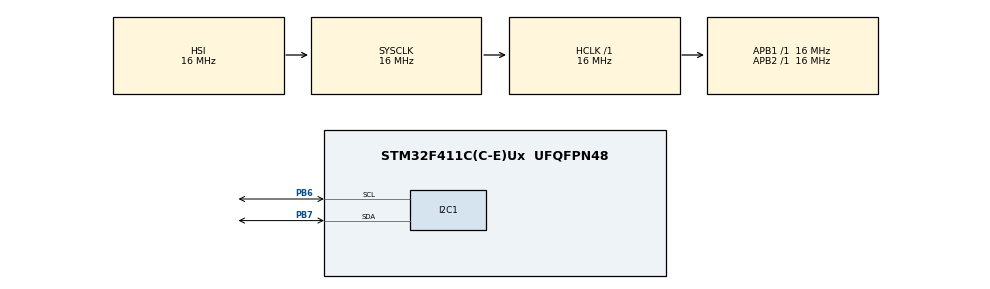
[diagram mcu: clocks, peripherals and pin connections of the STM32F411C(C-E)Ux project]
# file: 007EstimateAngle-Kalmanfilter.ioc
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Mcu.Family=STM32F4
Mcu.Name=STM32F411C(C-E)Ux
Mcu.Package=UFQFPN48
NVIC.PriorityGroup=NVIC_PRIORITYGROUP_4
PA13.Mode=Serial_Wire
PA13.Signal=SYS_JTMS-SWDIO
PA14.Mode=Serial_Wire
PA14.Signal=SYS_JTCK-SWCLK
PB6.Mode=I2C
PB6.Signal=I2C1_SCL
PB7.Mode=I2C
PB7.Signal=I2C1_SDA
PC14-OSC32_IN.Mode=LSE-External-Oscillator
PC14-OSC32_IN.Signal=RCC_OSC32_IN
PC15-OSC32_OUT.Mode=LSE-External-Oscillator
PC15-OSC32_OUT.Signal=RCC_OSC32_OUT
PH0\ -\ OSC_IN.Mode=HSE-External-Oscillator
PH0\ -\ OSC_IN.Signal=RCC_OSC_IN
PH1\ -\ OSC_OUT.Mode=HSE-External-Oscillator
PH1\ -\ OSC_OUT.Signal=RCC_OSC_OUT
ProjectManager.HeapSize=0x200
ProjectManager.StackSize=0x400
ProjectManager.TargetToolchain=STM32CubeIDE
RCC.AHBFreq_Value=16000000
RCC.APB1Freq_Value=16000000
RCC.APB2Freq_Value=16000000
RCC.CortexFreq_Value=16000000
RCC.HSE_VALUE=25000000
RCC.HSI_VALUE=16000000
RCC.SYSCLKFreq_VALUE=16000000
RCC.VCOOutputFreq_Value=192000000
board=custom

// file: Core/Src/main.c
/* USER CODE BEGIN Header */
/**
  ******************************************************************************
  * @file           : main.c
  * @brief          : Main program body
  ******************************************************************************
  * @attention
  *
  * Copyright (c) 2026 STMicroelectronics.
  * All rights reserved.
  *
  * This software is licensed under terms that can be found in the LICENSE file
  * in the root directory of this software component.
  * If no LICENSE file comes with this software, it is provided AS-IS.
  *
  ******************************************************************************
  */
/* USER CODE END Header */
#include "main.h"

/* USER CODE BEGIN Includes */
#include "MPU6050.h"
#include "kalman.h"
#include "math.h"
/* USER CODE END Includes */

I2C_HandleTypeDef hi2c1;

/* USER CODE BEGIN PV */

mpu6050_data mpu_data;

float Gx, Gy, Gz;
float Ax, Ay, Az;

float gyro_offset[3] = {0.0};

Kalman_t KalmanRoll;
Kalman_t KalmanPitch;

float roll, pitch;

float AccRoll;
float AccPitch;

/* USER CODE END PV */

void SystemClock_Config(void);
static void MX_GPIO_Init(void);
static void MX_I2C1_Init(void);
/* USER CODE BEGIN PFP */

void MPU_Read_Gyro(mpu6050_data *data, float *Gx, float *Gy, float *Gz)
{

	*Gx = ((float)data->gyro_x) / 131.0;
	*Gy = ((float)data->gyro_y) / 131.0;
	*Gz = ((float)data->gyro_z) / 131.0;

}

void MPU_Read_Accel(mpu6050_data *data, float *Ax, float *Ay, float *Az)
{

	*Ax = ((float)data->acel_x) / 16384.0;
	*Ay = ((float)data->acel_y) / 16384.0;
	*Az = ((float)data->acel_z) / 16384.0;
}
/* USER CODE END PFP */

int main(void)
{

  /* MCU Configuration--------------------------------------------------------*/

  /* Reset of all peripherals, Initializes the Flash interface and the Systick. */
  HAL_Init();

  /* Configure the system clock */
  SystemClock_Config();

  /* Initialize all configured peripherals */
  MX_GPIO_Init();
  MX_I2C1_Init();
  /* USER CODE BEGIN 2 */
  mpu6050_init(&hi2c1, MPU6050_ADDR);
  Kalman_Init(&KalmanRoll,0.0f,4.0f);
  Kalman_Init(&KalmanPitch,0.0f,4.0f);
  /* USER CODE END 2 */

  for(uint16_t i = 0; i <= 1999; i++)
  {
	  mpu6050_read_data(&hi2c1, MPU6050_ADDR, &mpu_data);
	  MPU_Read_Gyro(&mpu_data, &Gx, &Gy, &Gz);

	  gyro_offset[0] += Gx;
	  gyro_offset[1] += Gy;
	  gyro_offset[2] += Gz;

	  HAL_Delay(10);
  }

  gyro_offset[0] /= 2000;
  gyro_offset[1] /= 2000;
  gyro_offset[2] /= 2000;

  mpu6050_calibration(gyro_offset, &Gx, &Gy, &Gz);
  /* Infinite loop */
  /* USER CODE BEGIN WHILE */
  while (1)
  {

	  if(mpu6050_read_data(&hi2c1, MPU6050_ADDR, &mpu_data) == MPU6050_OK)
	  {
		  MPU_Read_Gyro(&mpu_data, &Gx, &Gy, &Gz);
		  MPU_Read_Accel(&mpu_data, &Ax, &Ay, &Az);
		  mpu6050_calibration(gyro_offset, &Gx, &Gy, &Gz);

		  AccRoll = atan2f(Ay, sqrtf(Ax * Ax + Az * Az))*180.0f/3.1415926f;

		  AccPitch = -atan2f(Ax, sqrtf(Ay * Ay + Az * Az))*180.0f/3.1415926f;

		  roll = Kalman_Update(&KalmanRoll,Gx,AccRoll,0.004f);
		  pitch = Kalman_Update(&KalmanPitch, Gy,AccPitch,0.004f);
	  }
	  HAL_Delay(1);

    /* USER CODE END WHILE */

  }
}

void SystemClock_Config(void)
{
  RCC_OscInitTypeDef RCC_OscInitStruct = {0};
  RCC_ClkInitTypeDef RCC_ClkInitStruct = {0};

  /** Configure the main internal regulator output voltage
  */
  __HAL_RCC_PWR_CLK_ENABLE();
  __HAL_PWR_VOLTAGESCALING_CONFIG(PWR_REGULATOR_VOLTAGE_SCALE1);

  /** Initializes the RCC Oscillators according to the specified parameters
  * in the RCC_OscInitTypeDef structure.
  */
  RCC_OscInitStruct.OscillatorType = RCC_OSCILLATORTYPE_HSI;
  RCC_OscInitStruct.HSIState = RCC_HSI_ON;
  RCC_OscInitStruct.HSICalibrationValue = RCC_HSICALIBRATION_DEFAULT;
  RCC_OscInitStruct.PLL.PLLState = RCC_PLL_NONE;
  if (HAL_RCC_OscConfig(&RCC_OscInitStruct) != HAL_OK)
  {
    Error_Handler();
  }

  /** Initializes the CPU, AHB and APB buses clocks
  */
  RCC_ClkInitStruct.ClockType = RCC_CLOCKTYPE_HCLK|RCC_CLOCKTYPE_SYSCLK
                              |RCC_CLOCKTYPE_PCLK1|RCC_CLOCKTYPE_PCLK2;
  RCC_ClkInitStruct.SYSCLKSource = RCC_SYSCLKSOURCE_HSI;
  RCC_ClkInitStruct.AHBCLKDivider = RCC_SYSCLK_DIV1;
  RCC_ClkInitStruct.APB1CLKDivider = RCC_HCLK_DIV1;
  RCC_ClkInitStruct.APB2CLKDivider = RCC_HCLK_DIV1;

  if (HAL_RCC_ClockConfig(&RCC_ClkInitStruct, FLASH_LATENCY_0) != HAL_OK)
  {
    Error_Handler();
  }
}

static void MX_I2C1_Init(void)
{

  hi2c1.Instance = I2C1;
  hi2c1.Init.ClockSpeed = 100000;
  hi2c1.Init.DutyCycle = I2C_DUTYCYCLE_2;
  hi2c1.Init.OwnAddress1 = 0;
  hi2c1.Init.AddressingMode = I2C_ADDRESSINGMODE_7BIT;
  hi2c1.Init.DualAddressMode = I2C_DUALADDRESS_DISABLE;
  hi2c1.Init.OwnAddress2 = 0;
  hi2c1.Init.GeneralCallMode = I2C_GENERALCALL_DISABLE;
  hi2c1.Init.NoStretchMode = I2C_NOSTRETCH_DISABLE;
  if (HAL_I2C_Init(&hi2c1) != HAL_OK)
  {
    Error_Handler();
  }

}

static void MX_GPIO_Init(void)
{

  /* GPIO Ports Clock Enable */
  __HAL_RCC_GPIOC_CLK_ENABLE();
  __HAL_RCC_GPIOH_CLK_ENABLE();
  __HAL_RCC_GPIOA_CLK_ENABLE();
  __HAL_RCC_GPIOB_CLK_ENABLE();

}

void Error_Handler(void)
{
  __disable_irq();
  while (1)
  {
  }
}
